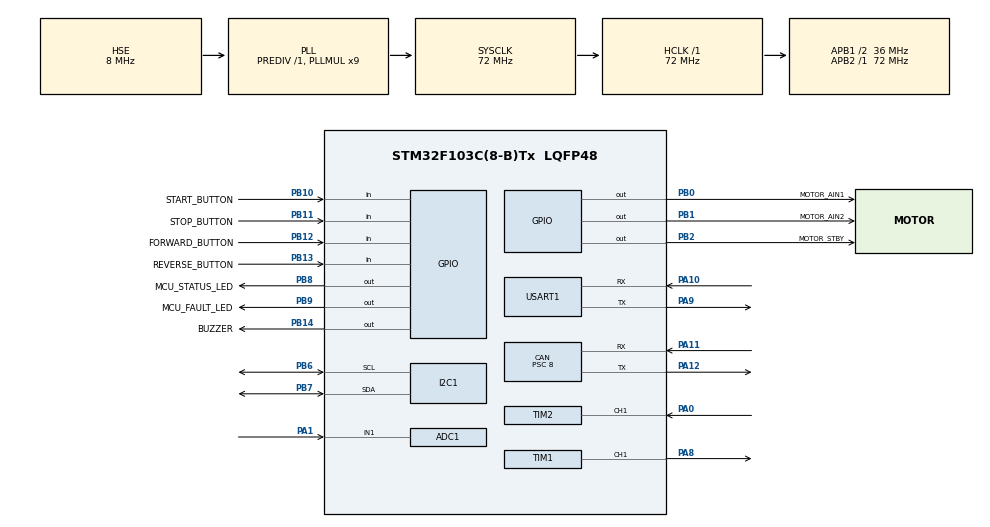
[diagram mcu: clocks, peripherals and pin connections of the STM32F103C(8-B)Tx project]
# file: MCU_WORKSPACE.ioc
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ADC1.Channel-0\#ChannelRegularConversion=ADC_CHANNEL_1
ADC1.NbrOfConversionFlag=1
ADC1.Rank-0\#ChannelRegularConversion=1
ADC1.SamplingTime-0\#ChannelRegularConversion=ADC_SAMPLETIME_55CYCLES_5
ADC1.master=1
CAN.BS1=CAN_BS1_7TQ
CAN.CalculateBaudRate=500000
CAN.CalculateTimeBit=2000
CAN.CalculateTimeQuantum=222.22222222222223
CAN.Mode=CAN_MODE_LOOPBACK
CAN.NART=ENABLE
CAN.Prescaler=8
Mcu.Family=STM32F1
Mcu.Name=STM32F103C(8-B)Tx
Mcu.Package=LQFP48
NVIC.PriorityGroup=NVIC_PRIORITYGROUP_4
NVIC.TIM2_IRQn=true\:0\:0\:false\:false\:true\:true\:true\:true
NVIC.USB_LP_CAN1_RX0_IRQn=true\:0\:0\:false\:false\:true\:true\:true\:true
PA0-WKUP.Signal=S_TIM2_CH1_ETR
PA1.Signal=ADCx_IN1
PA10.Mode=Asynchronous
PA10.Signal=USART1_RX
PA11.Mode=CAN_Activate
PA11.Signal=CAN_RX
PA12.Mode=CAN_Activate
PA12.Signal=CAN_TX
PA13.Mode=Serial_Wire
PA13.Signal=SYS_JTMS-SWDIO
PA14.Mode=Serial_Wire
PA14.Signal=SYS_JTCK-SWCLK
PA8.Signal=S_TIM1_CH1
PA9.Mode=Asynchronous
PA9.Signal=USART1_TX
PB0.GPIO_Label=MOTOR_AIN1
PB0.Signal=GPIO_Output
PB1.GPIO_Label=MOTOR_AIN2
PB1.Signal=GPIO_Output
PB10.GPIO_Label=START_BUTTON
PB10.GPIO_PuPd=GPIO_PULLUP
PB10.Signal=GPIO_Input
PB11.GPIO_Label=STOP_BUTTON
PB11.GPIO_PuPd=GPIO_PULLUP
PB11.Signal=GPIO_Input
PB12.GPIO_Label=FORWARD_BUTTON
PB12.GPIO_PuPd=GPIO_PULLUP
PB12.Signal=GPIO_Input
PB13.GPIO_Label=REVERSE_BUTTON
PB13.GPIO_PuPd=GPIO_PULLUP
PB13.Signal=GPIO_Input
PB14.GPIO_Label=BUZZER
PB14.Signal=GPIO_Output
PB2.GPIO_Label=MOTOR_STBY
PB2.Signal=GPIO_Output
PB6.Mode=I2C
PB6.Signal=I2C1_SCL
PB7.Mode=I2C
PB7.Signal=I2C1_SDA
PB8.GPIO_Label=MCU_STATUS_LED
PB8.Signal=GPIO_Output
PB9.GPIO_Label=MCU_FAULT_LED
PB9.Signal=GPIO_Output
PD0-OSC_IN.Mode=HSE-External-Oscillator
PD0-OSC_IN.Signal=RCC_OSC_IN
PD1-OSC_OUT.Mode=HSE-External-Oscillator
PD1-OSC_OUT.Signal=RCC_OSC_OUT
ProjectManager.HeapSize=0x200
ProjectManager.StackSize=0x400
ProjectManager.TargetToolchain=STM32CubeIDE
RCC.ADCPresc=RCC_ADCPCLK2_DIV6
RCC.AHBFreq_Value=72000000
RCC.APB1CLKDivider=RCC_HCLK_DIV2
RCC.APB1Freq_Value=36000000
RCC.APB1TimFreq_Value=72000000
RCC.APB2Freq_Value=72000000
RCC.APB2TimFreq_Value=72000000
RCC.HCLKFreq_Value=72000000
RCC.PLLMUL=RCC_PLL_MUL9
RCC.PLLSourceVirtual=RCC_PLLSOURCE_HSE
RCC.SYSCLKFreq_VALUE=72000000
RCC.SYSCLKSource=RCC_SYSCLKSOURCE_PLLCLK
RCC.USBFreq_Value=72000000
SH.ADCx_IN1.0=ADC1_IN1,IN1
SH.S_TIM1_CH1.0=TIM1_CH1,PWM Generation1 CH1
SH.S_TIM2_CH1_ETR.0=TIM2_CH1,Input_Capture1_from_TI1
TIM1.AutoReloadPreload=TIM_AUTORELOAD_PRELOAD_ENABLE
TIM1.Channel-PWM\ Generation1\ CH1=TIM_CHANNEL_1
TIM1.Period=3599
TIM2.Channel-Input_Capture1_from_TI1=TIM_CHANNEL_1
TIM2.Prescaler=71
USART1.VirtualMode=VM_ASYNC
board=custom

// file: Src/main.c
/* USER CODE BEGIN Header */

/**
  ******************************************************************************
  * @file           : main.c
  * @brief          : Main program body
  ******************************************************************************
  * @attention
  *
  * Copyright (c) 2026 STMicroelectronics.
  * All rights reserved.
  *
  ******************************************************************************
  */

/* USER CODE END Header */

#include "main.h"
#include "adc.h"
#include "can.h"
#include "i2c.h"
#include "tim.h"
#include "usart.h"
#include "gpio.h"

/* USER CODE BEGIN Includes */

#include "mcu_system.h"

/* USER CODE END Includes */

void SystemClock_Config(void);

int main(void)
{

  /* MCU Configuration--------------------------------------------------------*/

  /* Reset of all peripherals, Initializes the Flash interface and the Systick. */

  HAL_Init();

  /* Configure the system clock */

  SystemClock_Config();

  /* Initialize all configured peripherals */

  MX_GPIO_Init();
  MX_CAN_Init();
  MX_I2C1_Init();
  MX_TIM1_Init();
  MX_TIM2_Init();
  MX_USART1_UART_Init();
  MX_ADC1_Init();

  /* USER CODE BEGIN 2 */

  /*
   * Initialize the complete MCU application layer.
   *
   * This initializes:
   *   - application data
   *   - motor control
   *   - Hall sensor
   *   - ADC/potentiometer
   *   - CAN
   *   - buttons
   *   - fault management
   *   - LCD
   *   - UART debug
   *   - state machine
   */

  MCU_System_Init();

  /* USER CODE END 2 */

  /* Infinite loop */

  /* USER CODE BEGIN WHILE */

  while (1)
  {
    MCU_System_Run();
  }

  /* USER CODE END WHILE */

}

void SystemClock_Config(void)
{
  RCC_OscInitTypeDef RCC_OscInitStruct = {0};
  RCC_ClkInitTypeDef RCC_ClkInitStruct = {0};
  RCC_PeriphCLKInitTypeDef PeriphClkInit = {0};

  /** Initializes the RCC Oscillators according to the specified parameters
  * in the RCC_OscInitTypeDef structure.
  */

  RCC_OscInitStruct.OscillatorType = RCC_OSCILLATORTYPE_HSE;
  RCC_OscInitStruct.HSEState = RCC_HSE_ON;
  RCC_OscInitStruct.HSEPredivValue = RCC_HSE_PREDIV_DIV1;
  RCC_OscInitStruct.HSIState = RCC_HSI_ON;
  RCC_OscInitStruct.PLL.PLLState = RCC_PLL_ON;
  RCC_OscInitStruct.PLL.PLLSource = RCC_PLLSOURCE_HSE;
  RCC_OscInitStruct.PLL.PLLMUL = RCC_PLL_MUL9;

  if (HAL_RCC_OscConfig(&RCC_OscInitStruct) != HAL_OK)
  {
    Error_Handler();
  }

  /** Initializes the CPU, AHB and APB buses clocks
  */

  RCC_ClkInitStruct.ClockType = RCC_CLOCKTYPE_HCLK |
                                RCC_CLOCKTYPE_SYSCLK |
                                RCC_CLOCKTYPE_PCLK1 |
                                RCC_CLOCKTYPE_PCLK2;

  RCC_ClkInitStruct.SYSCLKSource = RCC_SYSCLKSOURCE_PLLCLK;
  RCC_ClkInitStruct.AHBCLKDivider = RCC_SYSCLK_DIV1;
  RCC_ClkInitStruct.APB1CLKDivider = RCC_HCLK_DIV2;
  RCC_ClkInitStruct.APB2CLKDivider = RCC_HCLK_DIV1;

  if (HAL_RCC_ClockConfig(&RCC_ClkInitStruct, FLASH_LATENCY_2) != HAL_OK)
  {
    Error_Handler();
  }

  PeriphClkInit.PeriphClockSelection = RCC_PERIPHCLK_ADC;
  PeriphClkInit.AdcClockSelection = RCC_ADCPCLK2_DIV6;

  if (HAL_RCCEx_PeriphCLKConfig(&PeriphClkInit) != HAL_OK)
  {
    Error_Handler();
  }
}

void Error_Handler(void)
{
  /* USER CODE BEGIN Error_Handler_Debug */

  /*
   * Disable interrupts and remain stopped in a safe state.
   *
   * GPIO startup defaults already keep the motor driver disabled:
   *   AIN1 = 0
   *   AIN2 = 0
   *   STBY = 0
   *   PWM = 0
   */

  __disable_irq();

  while (1)
  {
  }

  /* USER CODE END Error_Handler_Debug */
}

#ifdef USE_FULL_ASSERT

/**
  * @brief  Reports the name of the source file and the source line number
  *         where the assert_param error has occurred.
  * @param  file: pointer to the source file name
  * @param  line: assert_param error line source number
  * @retval None
  */
void assert_failed(uint8_t *file, uint32_t line)
{
  /* USER CODE BEGIN 6 */

  /*
   * Full assert is disabled in the current project configuration.
   * This function is retained for compatibility with STM32CubeMX.
   */

  (void)file;
  (void)line;

  /* USER CODE END 6 */
}

#endif /* USE_FULL_ASSERT */
